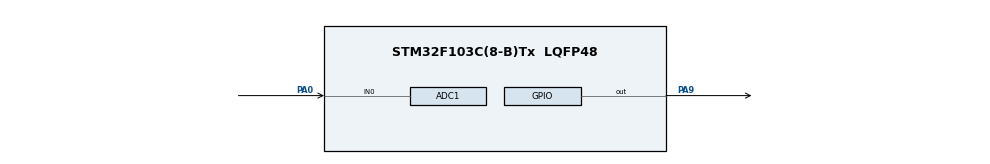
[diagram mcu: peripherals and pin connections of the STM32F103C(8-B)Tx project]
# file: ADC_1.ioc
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ADC1.Channel-0\#ChannelRegularConversion=ADC_CHANNEL_0
ADC1.NbrOfConversion=1
ADC1.NbrOfConversionFlag=1
ADC1.Rank-0\#ChannelRegularConversion=1
ADC1.SamplingTime-0\#ChannelRegularConversion=ADC_SAMPLETIME_1CYCLE_5
ADC1.master=1
Mcu.Family=STM32F1
Mcu.Name=STM32F103C(8-B)Tx
Mcu.Package=LQFP48
NVIC.PriorityGroup=NVIC_PRIORITYGROUP_4
PA0-WKUP.Signal=ADCx_IN0
PA13.Mode=Serial_Wire
PA13.Signal=SYS_JTMS-SWDIO
PA14.Mode=Serial_Wire
PA14.Signal=SYS_JTCK-SWCLK
PA9.Signal=GPIO_Output
ProjectManager.HeapSize=0x200
ProjectManager.StackSize=0x400
ProjectManager.TargetToolchain=MDK-ARM V5.32
RCC.APB1Freq_Value=8000000
RCC.APB2Freq_Value=8000000
SH.ADCx_IN0.0=ADC1_IN0,IN0
board=custom

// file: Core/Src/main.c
/* USER CODE BEGIN Header */
/**
  ******************************************************************************
  * @file           : main.c
  * @brief          : Main program body
  ******************************************************************************
  * @attention
  *
  * Copyright (c) 2025 STMicroelectronics.
  * All rights reserved.
  *
  * This software is licensed under terms that can be found in the LICENSE file
  * in the root directory of this software component.
  * If no LICENSE file comes with this software, it is provided AS-IS.
  *
  ******************************************************************************
  */
/* USER CODE END Header */
#include "main.h"
#include "adc.h"
#include "gpio.h"

void SystemClock_Config(void);

int main(void)
{

  /* MCU Configuration--------------------------------------------------------*/

  /* Reset of all peripherals, Initializes the Flash interface and the Systick. */
  HAL_Init();

  /* Configure the system clock */
  SystemClock_Config();

  /* Initialize all configured peripherals */
  MX_GPIO_Init();
  MX_ADC1_Init();

  /* Infinite loop */
  /* USER CODE BEGIN WHILE */
  while (1)
  {
		//1.启动常规序列
		HAL_ADC_Start(&hadc1);

		//2.等待转换完成
		HAL_ADC_PollForConversion(&hadc1,HAL_MAX_DELAY);

		//3.获取转换结果
		uint32_t dr=HAL_ADC_GetValue(&hadc1);

		//4.把结果转换为电压
		float voltage=dr*(3.3f-0.0f)/4095.0f;

		if(voltage>1.5)
		{
			HAL_GPIO_WritePin(GPIOA,GPIO_PIN_9,GPIO_PIN_RESET);
		}
		else
		{
			HAL_GPIO_WritePin(GPIOA,GPIO_PIN_9,GPIO_PIN_SET);
		}
    /* USER CODE END WHILE */

  }
}

void SystemClock_Config(void)
{
  RCC_OscInitTypeDef RCC_OscInitStruct = {0};
  RCC_ClkInitTypeDef RCC_ClkInitStruct = {0};
  RCC_PeriphCLKInitTypeDef PeriphClkInit = {0};

  /** Initializes the RCC Oscillators according to the specified parameters
  * in the RCC_OscInitTypeDef structure.
  */
  RCC_OscInitStruct.OscillatorType = RCC_OSCILLATORTYPE_HSI;
  RCC_OscInitStruct.HSIState = RCC_HSI_ON;
  RCC_OscInitStruct.HSICalibrationValue = RCC_HSICALIBRATION_DEFAULT;
  RCC_OscInitStruct.PLL.PLLState = RCC_PLL_NONE;
  if (HAL_RCC_OscConfig(&RCC_OscInitStruct) != HAL_OK)
  {
    Error_Handler();
  }

  /** Initializes the CPU, AHB and APB buses clocks
  */
  RCC_ClkInitStruct.ClockType = RCC_CLOCKTYPE_HCLK|RCC_CLOCKTYPE_SYSCLK
                              |RCC_CLOCKTYPE_PCLK1|RCC_CLOCKTYPE_PCLK2;
  RCC_ClkInitStruct.SYSCLKSource = RCC_SYSCLKSOURCE_HSI;
  RCC_ClkInitStruct.AHBCLKDivider = RCC_SYSCLK_DIV1;
  RCC_ClkInitStruct.APB1CLKDivider = RCC_HCLK_DIV1;
  RCC_ClkInitStruct.APB2CLKDivider = RCC_HCLK_DIV1;

  if (HAL_RCC_ClockConfig(&RCC_ClkInitStruct, FLASH_LATENCY_0) != HAL_OK)
  {
    Error_Handler();
  }
  PeriphClkInit.PeriphClockSelection = RCC_PERIPHCLK_ADC;
  PeriphClkInit.AdcClockSelection = RCC_ADCPCLK2_DIV2;
  if (HAL_RCCEx_PeriphCLKConfig(&PeriphClkInit) != HAL_OK)
  {
    Error_Handler();
  }
}

void Error_Handler(void)
{
  __disable_irq();
  while (1)
  {
  }
}
